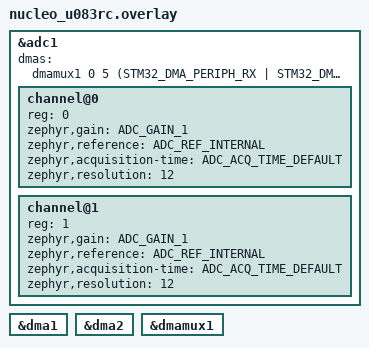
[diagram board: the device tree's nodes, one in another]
/*
 * SPDX-License-Identifier: Apache-2.0
 *
 * Copyright (c) 2024 STMicroelectronics
 */

&adc1 {
	#address-cells = <1>;
	#size-cells = <0>;

	channel@0 {
		reg = <0>;
		zephyr,gain = "ADC_GAIN_1";
		zephyr,reference = "ADC_REF_INTERNAL";
		zephyr,acquisition-time = <ADC_ACQ_TIME_DEFAULT>;
		zephyr,resolution = <12>;
	};

	channel@1 {
		reg = <1>;
		zephyr,gain = "ADC_GAIN_1";
		zephyr,reference = "ADC_REF_INTERNAL";
		zephyr,acquisition-time = <ADC_ACQ_TIME_DEFAULT>;
		zephyr,resolution = <12>;
	};
};

/*
 * SPDX-License-Identifier: Apache-2.0
 *
 * Copyright (c) 2024 STMicroelectronics
 */

&adc1 {
	dmas = <&dmamux1 0 5 (STM32_DMA_PERIPH_RX | STM32_DMA_MEM_16BITS |
			      STM32_DMA_PERIPH_16BITS)>;
	dma-names = "dmamux";
};

&dma1 {
	status = "okay";
};

&dma2 {
	status = "okay";
};

&dmamux1 {
	status = "okay";
};
